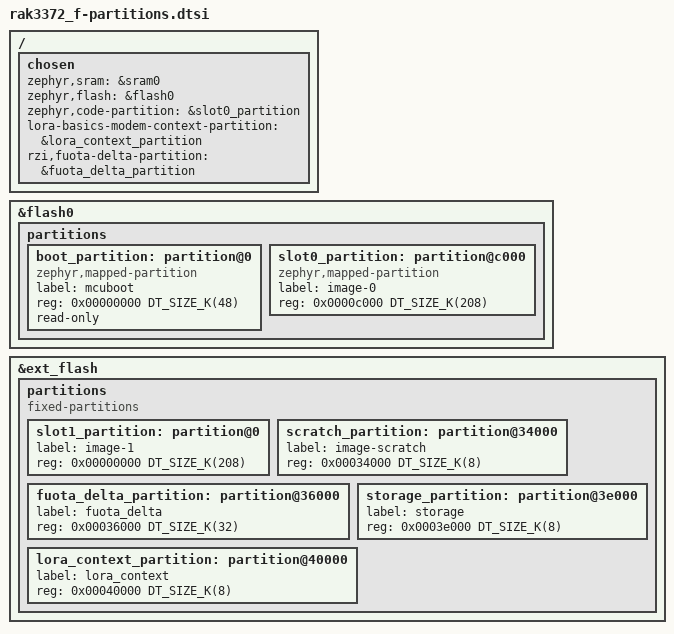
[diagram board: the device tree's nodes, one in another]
/*
 * rak3372_f flash map.
 *
 * Internal STM32WLE5 flash is 256 KiB: 48K boot + 208K slot0. MCUboot is
 * larger than on RAK3372 because it has to read the MX25L400. The 512 KiB
 * NOR holds a 208K slot1, an 8 KiB scratch area (two 4 KiB sectors), a
 * 32 KiB FUOTA delta area, then 8 KiB settings and 8 KiB LoRaWAN context.
 * MCUboot swaps the slots through scratch. An unconfirmed test image
 * reverts on the next boot. LoRaWAN FUOTA writes the signed image to
 * image-1.
 */

/*
 * RAK3372-F flash map (overwrite-only MCUBoot).
 *
 * Internal STM32WLE5 flash (256 KB):
 *   48K boot + 208K slot0.
 *
 * On-module MX25L400 (512 KB):
 *   208K slot1 + 8K storage + 8K lora_context.
 * Remaining external space is unused.
 *
 * Settings / NVS and LoRa Basics Modem context live on external flash so
 * slot0 can use the full remaining internal flash after the bootloader.
 * slot0 and slot1 stay the same size for overwrite-only MCUBoot.
 *
 * The board .yml requires the SPI NOR so MCUboot can read image-1.
 */
/ {
	chosen {
		zephyr,sram = &sram0;
		zephyr,flash = &flash0;
		zephyr,code-partition = &slot0_partition;
		lora-basics-modem-context-partition = &lora_context_partition;
		rzi,fuota-delta-partition = &fuota_delta_partition;
	};
};

&flash0 {
	partitions {
		ranges;
		#address-cells = <1>;
		#size-cells = <1>;

		boot_partition: partition@0 {
			compatible = "zephyr,mapped-partition";
			label = "mcuboot";
			reg = <0x00000000 DT_SIZE_K(48)>;
			read-only;
		};

		slot0_partition: partition@c000 {
			compatible = "zephyr,mapped-partition";
			label = "image-0";
			reg = <0x0000c000 DT_SIZE_K(208)>;
		};
	};
};

&ext_flash {
	partitions {
		compatible = "fixed-partitions";
		#address-cells = <1>;
		#size-cells = <1>;

		slot1_partition: partition@0 {
			label = "image-1";
			reg = <0x00000000 DT_SIZE_K(208)>;
		};

		/* Two 4 KiB NOR sectors. MCUboot uses this only in swap-using-scratch. */
		scratch_partition: partition@34000 {
			label = "image-scratch";
			reg = <0x00034000 DT_SIZE_K(8)>;
		};

		/* Reassembly space for a FUOTA delta. Not consumed by the current apply path. */
		fuota_delta_partition: partition@36000 {
			label = "fuota_delta";
			reg = <0x00036000 DT_SIZE_K(32)>;
		};

		storage_partition: partition@3e000 {
			label = "storage";
			reg = <0x0003e000 DT_SIZE_K(8)>;
		};

		lora_context_partition: partition@40000 {
			label = "lora_context";
			reg = <0x00040000 DT_SIZE_K(8)>;
		};
	};
};
